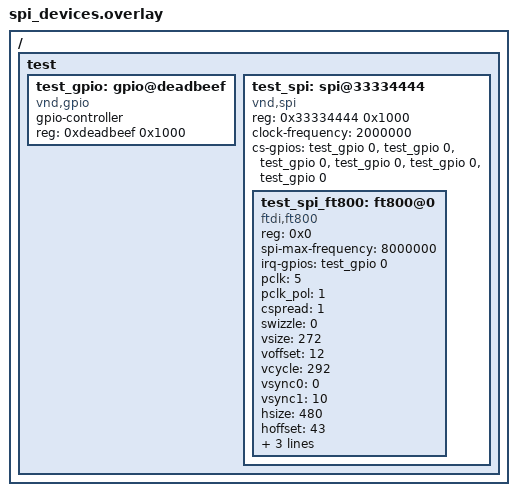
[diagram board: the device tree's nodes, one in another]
/*
 * Copyright (c) 2024 TOKITA Hiroshi
 * SPDX-License-Identifier: Apache-2.0
 */

/ {
	test {
		#address-cells = <1>;
		#size-cells = <1>;

		test_gpio: gpio@deadbeef {
			compatible = "vnd,gpio";
			gpio-controller;
			reg = <0xdeadbeef 0x1000>;
			#gpio-cells = <0x2>;
			status = "okay";
		};

		test_spi: spi@33334444 {
			#address-cells = <1>;
			#size-cells = <0>;
			compatible = "vnd,spi";
			reg = <0x33334444 0x1000>;
			status = "okay";
			clock-frequency = <2000000>;

			/* one entry for every devices at spi.dtsi */
			cs-gpios = <&test_gpio 0 0>,
				   <&test_gpio 0 0>,
				   <&test_gpio 0 0>,
				   <&test_gpio 0 0>,
				   <&test_gpio 0 0>,
				   <&test_gpio 0 0>;

			test_spi_ft800: ft800@0 {
				compatible = "ftdi,ft800";
				reg = <0x0>;
				spi-max-frequency = <8000000>;
				irq-gpios = <&test_gpio 0 0>;

				pclk = <5>;
				pclk_pol = <1>;
				cspread = <1>;
				swizzle = <0>;
				vsize = <272>;
				voffset = <12>;
				vcycle = <292>;
				vsync0 = <0>;
				vsync1 = <10>;
				hsize = <480>;
				hoffset = <43>;
				hcycle = <548>;
				hsync0 = <0>;
				hsync1 = <41>;

				status = "okay";
			};
		};
	};
};
